AUTOSAR XML (schema 4-3-0)
standard types defined: uint16, uint64, uint8, uint16_DataConstr, uint64_DataConstr, uint8_DataConstr
package /ComponentTypes
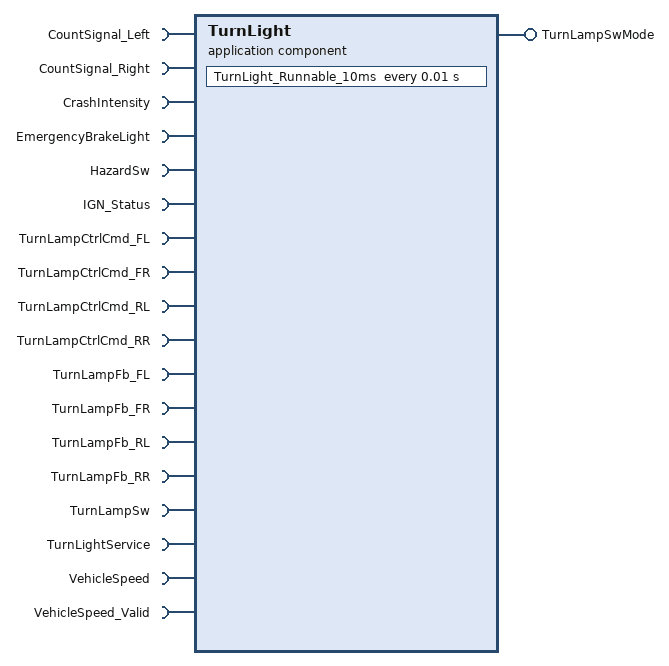
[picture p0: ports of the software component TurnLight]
  application sw component type TurnLight
    provide port TurnLampSwMode: nonqueued-sender-com-spec{data-element=TurnLampSwMode/u8_signa, init-value=0}, provided-interface=TurnLampSwMode
    18 x require port:
      CountSignal_Left: nonqueued-receiver-com-spec{data-element=CountSignal_Left/u8_Signal, filter=data-filter-type=ALWAYS, init-value=0}, required-interface=CountSignal_Left
      CountSignal_Right: nonqueued-receiver-com-spec{data-element=CountSignal_Right/u8_Signal, filter=data-filter-type=ALWAYS, init-value=0}, required-interface=CountSignal_Right
      CrashIntensity: nonqueued-receiver-com-spec{data-element=CrashIntensity/u8_Signal, filter=data-filter-type=ALWAYS, init-value=0}, required-interface=CrashIntensity
      EmergencyBrakeLight: nonqueued-receiver-com-spec{data-element=EmergencyBrakeLight/u8_Signal, filter=data-filter-type=ALWAYS, init-value=0}, required-interface=EmergencyBrakeLight
      HazardSw: nonqueued-receiver-com-spec{data-element=HazardSw/u8_Signal, filter=data-filter-type=ALWAYS, init-value=0}, required-interface=HazardSw
      IGN_Status: nonqueued-receiver-com-spec{data-element=IGN_Status/u8_signal, filter=data-filter-type=ALWAYS, init-value=0}, required-interface=IGN_Status
      TurnLampCtrlCmd_FL: nonqueued-receiver-com-spec{data-element=TurnLampCtrlCmd_FL/u8_signal, filter=data-filter-type=ALWAYS, init-value=0}, required-interface=TurnLampCtrlCmd_FL
      TurnLampCtrlCmd_FR: nonqueued-receiver-com-spec{data-element=TurnLampCtrlCmd_FR/u8_signa, filter=data-filter-type=ALWAYS, init-value=0}, required-interface=TurnLampCtrlCmd_FR
      TurnLampCtrlCmd_RL: nonqueued-receiver-com-spec{data-element=TurnLampCtrlCmd_RL/u8_signal, filter=data-filter-type=ALWAYS, init-value=0}, required-interface=TurnLampCtrlCmd_RL
      TurnLampCtrlCmd_RR: nonqueued-receiver-com-spec{data-element=TurnLampCtrlCmd_RR/u8_signal, filter=data-filter-type=ALWAYS, init-value=0}, required-interface=TurnLampCtrlCmd_RR
      TurnLampFb_FL: nonqueued-receiver-com-spec{data-element=TurnLampFb_FL/u8_Signal, filter=data-filter-type=ALWAYS, init-value=0}, required-interface=TurnLampFb_FL
      TurnLampFb_FR: nonqueued-receiver-com-spec{data-element=TurnLampFb_FR/u8_Signal, filter=data-filter-type=ALWAYS, init-value=0}, required-interface=TurnLampFb_FR
      TurnLampFb_RL: nonqueued-receiver-com-spec{data-element=TurnLampFb_RL/u8_Signal, filter=data-filter-type=ALWAYS, init-value=0}, required-interface=TurnLampFb_RL
      TurnLampFb_RR: nonqueued-receiver-com-spec{data-element=TurnLampFb_RR/u8_Signal, filter=data-filter-type=ALWAYS, init-value=0}, required-interface=TurnLampFb_RR
      TurnLampSw: nonqueued-receiver-com-spec{data-element=TurnLampSw/u8_Signal, filter=data-filter-type=ALWAYS, init-value=0}, required-interface=TurnLampSw
      TurnLightService: client-com-spec=TurnLightControl_Operation, required-interface=TurnLightService
      VehicleSpeed: nonqueued-receiver-com-spec{data-element=u16_signal, filter=data-filter-type=ALWAYS, init-value=0}, required-interface=VehicleSpeed
      VehicleSpeed_Valid: nonqueued-receiver-com-spec{data-element=VehicleSpeed_Valid/u8_Signal, filter=data-filter-type=ALWAYS, init-value=0}, required-interface=VehicleSpeed_Valid
    behavior TurnLight_InternalBehavior
      timing event TMT_TurnLight_Runnable_10ms: start-on-event=TurnLight_Runnable_10ms, period=0.01
      runnable TurnLight_Runnable_10ms: minimum-start-interval=0.01
        data-receive-point-by-arguments:
          17 x access:
            REC_CountSignal_Left_u8_Signal: accessed-variable=CountSignal_Left.u8_Signal
            REC_CountSignal_Right_u8_Signal: accessed-variable=CountSignal_Right.u8_Signal
            REC_CrashIntensity_u8_Signal: accessed-variable=CrashIntensity.u8_Signal
            REC_EmergencyBrakeLight_u8_Signal: accessed-variable=EmergencyBrakeLight.u8_Signal
            REC_HazardSw_u8_Signal: accessed-variable=HazardSw.u8_Signal
            REC_IGN_Status_u8_signal: accessed-variable=IGN_Status.u8_signal
            REC_TurnLampCtrlCmd_FL_u8_signal: accessed-variable=TurnLampCtrlCmd_FL.u8_signal
            REC_TurnLampCtrlCmd_FR_u8_signa: accessed-variable=TurnLampCtrlCmd_FR.u8_signa
            REC_TurnLampCtrlCmd_RL_u8_signal: accessed-variable=TurnLampCtrlCmd_RL.u8_signal
            REC_TurnLampCtrlCmd_RR_u8_signal: accessed-variable=TurnLampCtrlCmd_RR.u8_signal
            REC_TurnLampFb_FL_u8_Signal: accessed-variable=TurnLampFb_FL.u8_Signal
            REC_TurnLampFb_FR_u8_Signal: accessed-variable=TurnLampFb_FR.u8_Signal
            REC_TurnLampFb_RL_u8_Signal: accessed-variable=TurnLampFb_RL.u8_Signal
            REC_TurnLampFb_RR_u8_Signal: accessed-variable=TurnLampFb_RR.u8_Signal
            REC_TurnLampSw_u8_Signal: accessed-variable=TurnLampSw.u8_Signal
            REC_VehicleSpeed_u16_signal: accessed-variable=VehicleSpeed.u16_signal
            REC_VehicleSpeed_Valid_u8_Signal: accessed-variable=VehicleSpeed_Valid.u8_Signal
        data-send-points:
          access SEND_TurnLampSwMode_u8_signa: accessed-variable=TurnLampSwMode.u8_signa
        sync call SC_TurnLightService_TurnLightControl_Operation: operation=TurnLightService.TurnLightControl_Operation, timeout=0.01
  swc implementation TurnLight_Implementation: behavior=TurnLight_InternalBehavior
    code-descriptors:
      code Default: artifact-descriptors=autosar-engineering-object={short-label=Default, category=SWSRC}
package /DataTypes
  impl type ComplexTurnLightONOFFType: compu {0=NORQUEST, 1=OFF, 2=ON}, implementation-data-type=uint8, type-emitter=RTE
  impl type ComplexTurnLightPositionType: compu-method=ComplexTurnLightPosition, implementation-data-type=uint8, type-emitter=RTE
  impl type TurnLightService: category=STRUCTURE, sw-calibration-access=READ-ONLY, type-emitter=RTE
    7 x element, all with category=TYPE_REFERENCE:
      TurnLightPosition: compu-method=ComplexTurnLightPosition, implementation-data-type=ComplexTurnLightPositionType
      TurnLightOnOff: compu {0=NORQUEST, 1=OFF, 2=ON}, implementation-data-type=ComplexTurnLightONOFFType
      TurnLightDutyCycle: implementation-data-type=uint8, invalid-value=0
      TurnLightCycle: implementation-data-type=uint8, invalid-value=0
      TurnLightTimes: implementation-data-type=uint8, invalid-value=0
      TurnLightNumber: implementation-data-type=uint8, invalid-value=0
      TurnLightPriority: implementation-data-type=uint8, invalid-value=0
package /DataTypes/CompuMethods
  compu method ComplexTurnLightPosition: 0=NOREQUEST, 1=LEFT, 2=RIGHT, 3=ALL, 4=FRONT_LEFT, 5=MIDDLE_LEFT, 6=REAR_LEFT, 7=FRONT_RIGHT, 8=MIDDLE_RIGHT, 9=REAR_RIGHT
package /PortInterfaces
  client server interface TurnLightService
    operation TurnLightControl_Operation
      arg TurnLightCtrlPara: sw-calibration-access=READ-WRITE, type=TurnLightService, direction=IN, server-argument-impl-policy=USE-ARGUMENT-TYPE
  18 x sender receiver interface:
    CountSignal_Left: invalidation-policy{data-element=CountSignal_Left/u8_Signal, handle-invalid=DONT-INVALIDATE}
      data u8_Signal: type=uint8
    CountSignal_Right: invalidation-policy{data-element=CountSignal_Right/u8_Signal, handle-invalid=DONT-INVALIDATE}
      data u8_Signal: type=uint8
    CrashIntensity: invalidation-policy{data-element=CrashIntensity/u8_Signal, handle-invalid=DONT-INVALIDATE}
      data u8_Signal: type=uint8
    EmergencyBrakeLight: invalidation-policy{data-element=EmergencyBrakeLight/u8_Signal, handle-invalid=DONT-INVALIDATE}
      data u8_Signal: type=uint8
    HazardSw: invalidation-policy{data-element=HazardSw/u8_Signal, handle-invalid=DONT-INVALIDATE}
      data u8_Signal: type=uint8
    IGN_Status: invalidation-policy{data-element=IGN_Status/u8_signal, handle-invalid=DONT-INVALIDATE}
      data u8_signal: type=uint8
    TurnLampCtrlCmd_FL: invalidation-policy{data-element=TurnLampCtrlCmd_FL/u8_signal, handle-invalid=DONT-INVALIDATE}
      data u8_signal: type=uint8
    TurnLampCtrlCmd_FR: invalidation-policy{data-element=TurnLampCtrlCmd_FR/u8_signa, handle-invalid=DONT-INVALIDATE}
      data u8_signa: type=uint8
    TurnLampCtrlCmd_RL: invalidation-policy{data-element=TurnLampCtrlCmd_RL/u8_signal, handle-invalid=DONT-INVALIDATE}
      data u8_signal: type=uint8
    TurnLampCtrlCmd_RR: invalidation-policy{data-element=TurnLampCtrlCmd_RR/u8_signal, handle-invalid=DONT-INVALIDATE}
      data u8_signal: type=uint64
    TurnLampFb_FL: invalidation-policy{data-element=TurnLampFb_FL/u8_Signal, handle-invalid=DONT-INVALIDATE}
      data u8_Signal: type=uint8
    TurnLampFb_FR: invalidation-policy{data-element=TurnLampFb_FR/u8_Signal, handle-invalid=DONT-INVALIDATE}
      data u8_Signal: type=uint8
    TurnLampFb_RL: invalidation-policy{data-element=TurnLampFb_RL/u8_Signal, handle-invalid=DONT-INVALIDATE}
      data u8_Signal: type=uint8
    TurnLampFb_RR: invalidation-policy{data-element=TurnLampFb_RR/u8_Signal, handle-invalid=DONT-INVALIDATE}
      data u8_Signal: type=uint8
    TurnLampSw: invalidation-policy{data-element=TurnLampSw/u8_Signal, handle-invalid=DONT-INVALIDATE}
      data u8_Signal: type=uint8
    TurnLampSwMode: invalidation-policy{data-element=TurnLampSwMode/u8_signa, handle-invalid=DONT-INVALIDATE}
      data u8_signa: type=uint8
    VehicleSpeed: invalidation-policy{data-element=u16_signal, handle-invalid=DONT-INVALIDATE}
      data u16_signal: type=uint16
    VehicleSpeed_Valid: invalidation-policy{data-element=VehicleSpeed_Valid/u8_Signal, handle-invalid=DONT-INVALIDATE}
      data u8_Signal: type=uint8
